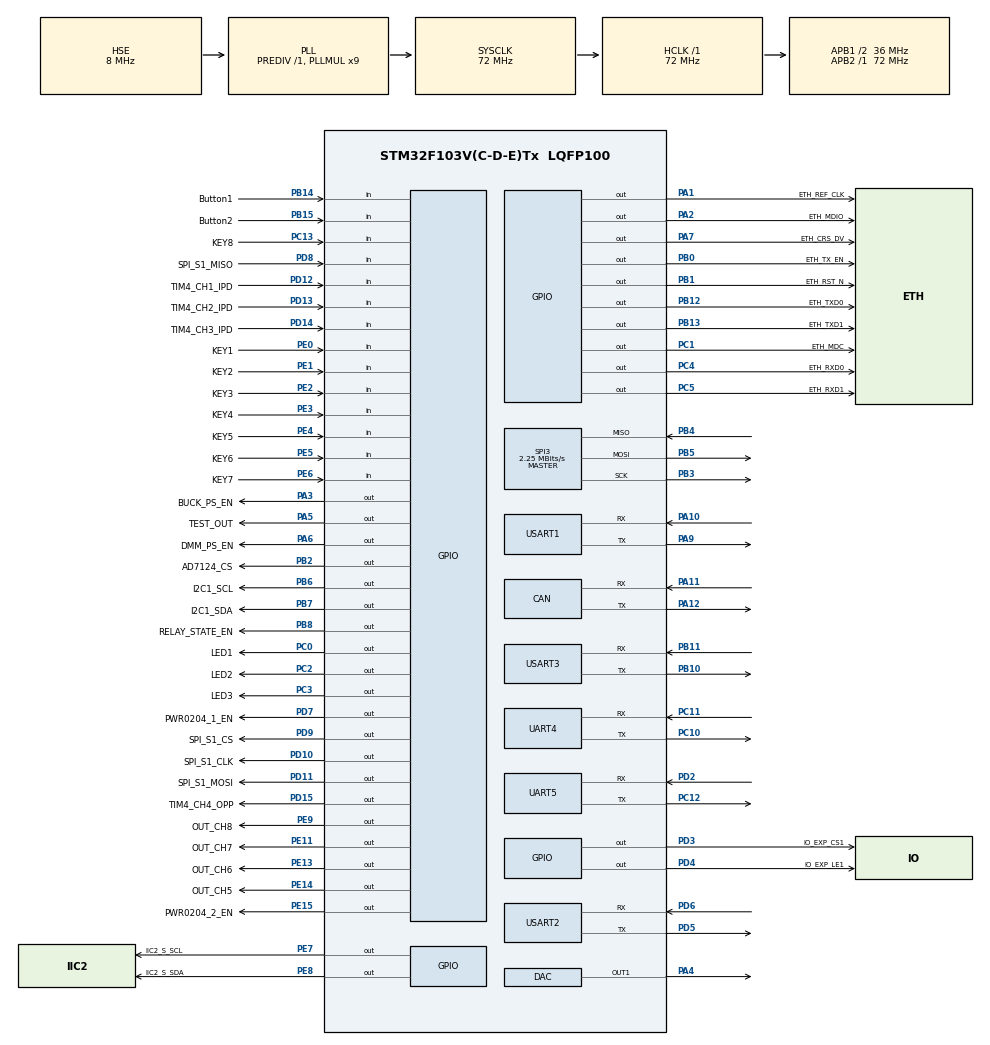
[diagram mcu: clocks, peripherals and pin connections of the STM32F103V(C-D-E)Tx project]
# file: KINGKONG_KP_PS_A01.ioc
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CAN.CalculateTimeBit=1333
CAN.CalculateTimeQuantum=444.44444444444446
DAC.DAC_Trigger=DAC_TRIGGER_NONE
FREERTOS.INCLUDE_vTaskDelayUntil=1
FREERTOS.Tasks01=defaultTask,0,128,StartDefaultTask,Default,NULL
FREERTOS.configTOTAL_HEAP_SIZE=15360
IWDG.Prescaler=IWDG_PRESCALER_32
IWDG.Reload=2500
Mcu.Family=STM32F1
Mcu.Name=STM32F103V(C-D-E)Tx
Mcu.Package=LQFP100
NVIC.PriorityGroup=NVIC_PRIORITYGROUP_4
NVIC.TIM6_IRQn=true\:0\:0\:false\:false\:true\:false\:false
NVIC.TimeBase=TIM6_IRQn
NVIC.TimeBaseIP=TIM6
NVIC.USART1_IRQn=true\:5\:0\:false\:false\:true\:true\:true
OSC_IN.Mode=HSE-External-Oscillator
OSC_IN.Signal=RCC_OSC_IN
OSC_OUT.Mode=HSE-External-Oscillator
OSC_OUT.Signal=RCC_OSC_OUT
PA1.GPIO_Label=ETH_REF_CLK
PA1.Signal=GPIO_Output
PA10.Mode=Asynchronous
PA10.Signal=USART1_RX
PA11.Mode=Master
PA11.Signal=CAN_RX
PA12.Mode=Master
PA12.Signal=CAN_TX
PA13.Mode=Serial_Wire
PA13.Signal=SYS_JTMS-SWDIO
PA14.Mode=Serial_Wire
PA14.Signal=SYS_JTCK-SWCLK
PA2.GPIO_Label=ETH_MDIO
PA2.Signal=GPIO_Output
PA3.GPIO_Label=BUCK_PS_EN
PA3.Signal=GPIO_Output
PA4.Signal=COMP_DAC1_group
PA5.GPIO_Label=TEST_OUT
PA5.GPIO_ModeDefaultOutputPP=GPIO_MODE_OUTPUT_PP
PA5.GPIO_Speed=GPIO_SPEED_FREQ_HIGH
PA5.Signal=GPIO_Output
PA6.GPIO_Label=DMM_PS_EN
PA6.GPIO_Speed=GPIO_SPEED_FREQ_HIGH
PA6.Signal=GPIO_Output
PA7.GPIO_Label=ETH_CRS_DV
PA7.Signal=GPIO_Output
PA9.Mode=Asynchronous
PA9.Signal=USART1_TX
PB0.GPIO_Label=ETH_TX_EN
PB0.Signal=GPIO_Output
PB1.GPIO_Label=ETH_RST_N
PB1.Signal=GPIO_Output
PB10.Mode=Asynchronous
PB10.Signal=USART3_TX
PB11.Mode=Asynchronous
PB11.Signal=USART3_RX
PB12.GPIO_Label=ETH_TXD0
PB12.Signal=GPIO_Output
PB13.GPIO_Label=ETH_TXD1
PB13.Signal=GPIO_Output
PB14.GPIO_Label=Button1
PB14.GPIO_Mode=GPIO_MODE_INPUT
PB14.GPIO_PuPd=GPIO_PULLUP
PB14.Signal=GPIO_Input
PB15.GPIO_Label=Button2
PB15.GPIO_Mode=GPIO_MODE_INPUT
PB15.GPIO_PuPd=GPIO_PULLUP
PB15.Signal=GPIO_Input
PB2.GPIO_Label=AD7124_CS
PB2.Signal=GPIO_Output
PB3.Mode=Full_Duplex_Master
PB3.Signal=SPI3_SCK
PB4.Mode=Full_Duplex_Master
PB4.Signal=SPI3_MISO
PB5.Mode=Full_Duplex_Master
PB5.Signal=SPI3_MOSI
PB6.GPIO_Label=I2C1_SCL
PB6.GPIO_ModeDefaultOutputPP=GPIO_MODE_OUTPUT_PP
PB6.GPIO_Speed=GPIO_SPEED_FREQ_HIGH
PB6.Signal=GPIO_Output
PB7.GPIO_Label=I2C1_SDA
PB7.GPIO_ModeDefaultOutputPP=GPIO_MODE_OUTPUT_PP
PB7.GPIO_Speed=GPIO_SPEED_FREQ_HIGH
PB7.Signal=GPIO_Output
PB8.GPIO_Label=RELAY_STATE_EN
PB8.GPIO_Speed=GPIO_SPEED_FREQ_HIGH
PB8.PinState=GPIO_PIN_RESET
PB8.Signal=GPIO_Output
PC0.GPIO_Label=LED1
PC0.GPIO_Speed=GPIO_SPEED_FREQ_HIGH
PC0.Signal=GPIO_Output
PC1.GPIO_Label=ETH_MDC
PC1.Signal=GPIO_Output
PC10.Mode=Asynchronous
PC10.Signal=UART4_TX
PC11.Mode=Asynchronous
PC11.Signal=UART4_RX
PC12.Mode=Asynchronous
PC12.Signal=UART5_TX
PC13-TAMPER-RTC.GPIO_Label=KEY8
PC13-TAMPER-RTC.Signal=GPIO_Input
PC2.GPIO_Label=LED2
PC2.GPIO_Speed=GPIO_SPEED_FREQ_HIGH
PC2.Signal=GPIO_Output
PC3.GPIO_Label=LED3
PC3.GPIO_Speed=GPIO_SPEED_FREQ_HIGH
PC3.Signal=GPIO_Output
PC4.GPIO_Label=ETH_RXD0
PC4.Signal=GPIO_Output
PC5.GPIO_Label=ETH_RXD1
PC5.Signal=GPIO_Output
PD10.GPIO_Label=SPI_S1_CLK
PD10.GPIO_Speed=GPIO_SPEED_FREQ_HIGH
PD10.Signal=GPIO_Output
PD11.GPIO_Label=SPI_S1_MOSI
PD11.GPIO_Speed=GPIO_SPEED_FREQ_HIGH
PD11.Signal=GPIO_Output
PD12.GPIO_Label=TIM4_CH1_IPD
PD12.GPIO_Mode=GPIO_MODE_INPUT
PD12.GPIO_PuPd=GPIO_PULLDOWN
PD12.Signal=GPIO_Input
PD13.GPIO_Label=TIM4_CH2_IPD
PD13.GPIO_Mode=GPIO_MODE_INPUT
PD13.GPIO_PuPd=GPIO_PULLDOWN
PD13.Signal=GPIO_Input
PD14.GPIO_Label=TIM4_CH3_IPD
PD14.GPIO_Mode=GPIO_MODE_INPUT
PD14.GPIO_PuPd=GPIO_PULLDOWN
PD14.Signal=GPIO_Input
PD15.GPIO_Label=TIM4_CH4_OPP
PD15.Signal=GPIO_Output
PD2.Mode=Asynchronous
PD2.Signal=UART5_RX
PD3.GPIO_Label=IO_EXP_CS1
PD3.GPIO_Speed=GPIO_SPEED_FREQ_HIGH
PD3.Signal=GPIO_Output
PD4.GPIO_Label=IO_EXP_LE1
PD4.GPIO_Speed=GPIO_SPEED_FREQ_HIGH
PD4.Signal=GPIO_Output
PD5.Mode=Asynchronous
PD5.Signal=USART2_TX
PD6.Mode=Asynchronous
PD6.Signal=USART2_RX
PD7.GPIO_Label=PWR0204_1_EN
PD7.GPIO_Speed=GPIO_SPEED_FREQ_HIGH
PD7.Signal=GPIO_Output
PD8.GPIO_Label=SPI_S1_MISO
PD8.Signal=GPIO_Input
PD9.GPIO_Label=SPI_S1_CS
PD9.GPIO_Speed=GPIO_SPEED_FREQ_HIGH
PD9.Signal=GPIO_Output
PE0.GPIO_Label=KEY1
PE0.Signal=GPIO_Input
PE1.GPIO_Label=KEY2
PE1.Signal=GPIO_Input
PE11.GPIO_Label=OUT_CH7
PE11.GPIO_ModeDefaultOutputPP=GPIO_MODE_OUTPUT_PP
PE11.GPIO_Speed=GPIO_SPEED_FREQ_HIGH
PE11.PinState=GPIO_PIN_RESET
PE11.Signal=GPIO_Output
PE13.GPIO_Label=OUT_CH6
PE13.GPIO_ModeDefaultOutputPP=GPIO_MODE_OUTPUT_PP
PE13.GPIO_Speed=GPIO_SPEED_FREQ_HIGH
PE13.PinState=GPIO_PIN_RESET
PE13.Signal=GPIO_Output
PE14.GPIO_Label=OUT_CH5
PE14.GPIO_ModeDefaultOutputPP=GPIO_MODE_OUTPUT_PP
PE14.GPIO_Speed=GPIO_SPEED_FREQ_HIGH
PE14.PinState=GPIO_PIN_RESET
PE14.Signal=GPIO_Output
PE15.GPIO_Label=PWR0204_2_EN
PE15.GPIO_Speed=GPIO_SPEED_FREQ_HIGH
PE15.Signal=GPIO_Output
PE2.GPIO_Label=KEY3
PE2.Signal=GPIO_Input
PE3.GPIO_Label=KEY4
PE3.Signal=GPIO_Input
PE4.GPIO_Label=KEY5
PE4.Signal=GPIO_Input
PE5.GPIO_Label=KEY6
PE5.Signal=GPIO_Input
PE6.GPIO_Label=KEY7
PE6.Signal=GPIO_Input
PE7.GPIO_Label=IIC2_S_SCL
PE7.GPIO_Speed=GPIO_SPEED_FREQ_HIGH
PE7.Signal=GPIO_Output
PE8.GPIO_Label=IIC2_S_SDA
PE8.GPIO_Speed=GPIO_SPEED_FREQ_HIGH
PE8.Signal=GPIO_Output
PE9.GPIO_Label=OUT_CH8
PE9.GPIO_ModeDefaultOutputPP=GPIO_MODE_OUTPUT_PP
PE9.GPIO_Speed=GPIO_SPEED_FREQ_HIGH
PE9.PinState=GPIO_PIN_RESET
PE9.Signal=GPIO_Output
ProjectManager.HeapSize=0x200
ProjectManager.StackSize=0x400
ProjectManager.TargetToolchain=MDK-ARM V5
RCC.AHBFreq_Value=72000000
RCC.APB1CLKDivider=RCC_HCLK_DIV2
RCC.APB1Freq_Value=36000000
RCC.APB1TimFreq_Value=72000000
RCC.APB2Freq_Value=72000000
RCC.APB2TimFreq_Value=72000000
RCC.HCLKFreq_Value=72000000
RCC.PLLMUL=RCC_PLL_MUL9
RCC.PLLSourceVirtual=RCC_PLLSOURCE_HSE
RCC.SYSCLKFreq_VALUE=72000000
RCC.SYSCLKSource=RCC_SYSCLKSOURCE_PLLCLK
RCC.USBFreq_Value=72000000
SH.COMP_DAC1_group.0=DAC_OUT1,DAC_OUT1
SPI3.BaudRatePrescaler=SPI_BAUDRATEPRESCALER_16
SPI3.CLKPhase=SPI_PHASE_2EDGE
SPI3.CLKPolarity=SPI_POLARITY_HIGH
SPI3.CalculateBaudRate=2.25 MBits/s
SPI3.Direction=SPI_DIRECTION_2LINES
SPI3.Mode=SPI_MODE_MASTER
SPI3.VirtualType=VM_MASTER
UART4.VirtualMode=Asynchronous
UART5.VirtualMode=Asynchronous
USART1.VirtualMode=VM_ASYNC
USART2.VirtualMode=VM_ASYNC
USART3.VirtualMode=VM_ASYNC
VP_FREERTOS_VS_ENABLE.Mode=Enabled
VP_IWDG_VS_IWDG.Mode=IWDG_Activate
VP_SYS_VS_tim6.Mode=TIM6
board=KINGKONG_KP_PS_A01

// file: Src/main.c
/* USER CODE BEGIN Header */
/**
  ******************************************************************************
  * @file           : main.c
  * @brief          : Main program body
  ******************************************************************************
  * This notice applies to any and all portions of this file
  * that are not between comment pairs USER CODE BEGIN and
  * USER CODE END. Other portions of this file, whether
  * inserted by the user or by software development tools
  * are owned by their respective copyright owners.
  *
  * Copyright (c) 2019 STMicroelectronics International N.V.
  * All rights reserved.
  *
  * Redistribution and use in source and binary forms, with or without
  * modification, are permitted, provided that the following conditions are met:
  *
  * 1. Redistribution of source code must retain the above copyright notice,
  *    this list of conditions and the following disclaimer.
  * 2. Redistributions in binary form must reproduce the above copyright notice,
  *    this list of conditions and the following disclaimer in the documentation
  *    and/or other materials provided with the distribution.
  * 3. Neither the name of STMicroelectronics nor the names of other
  *    contributors to this software may be used to endorse or promote products
  *    derived from this software without specific written permission.
  * 4. This software, including modifications and/or derivative works of this
  *    software, must execute solely and exclusively on microcontroller or
  *    microprocessor devices manufactured by or for STMicroelectronics.
  * 5. Redistribution and use of this software other than as permitted under
  *    this license is void and will automatically terminate your rights under
  *    this license.
  *
  * THIS SOFTWARE IS PROVIDED BY STMICROELECTRONICS AND CONTRIBUTORS "AS IS"
  * AND ANY EXPRESS, IMPLIED OR STATUTORY WARRANTIES, INCLUDING, BUT NOT
  * LIMITED TO, THE IMPLIED WARRANTIES OF MERCHANTABILITY, FITNESS FOR A
  * PARTICULAR PURPOSE AND NON-INFRINGEMENT OF THIRD PARTY INTELLECTUAL PROPERTY
  * RIGHTS ARE DISCLAIMED TO THE FULLEST EXTENT PERMITTED BY LAW. IN NO EVENT
  * SHALL STMICROELECTRONICS OR CONTRIBUTORS BE LIABLE FOR ANY DIRECT, INDIRECT,
  * INCIDENTAL, SPECIAL, EXEMPLARY, OR CONSEQUENTIAL DAMAGES (INCLUDING, BUT NOT
  * LIMITED TO, PROCUREMENT OF SUBSTITUTE GOODS OR SERVICES; LOSS OF USE, DATA,
  * OR PROFITS; OR BUSINESS INTERRUPTION) HOWEVER CAUSED AND ON ANY THEORY OF
  * LIABILITY, WHETHER IN CONTRACT, STRICT LIABILITY, OR TORT (INCLUDING
  * NEGLIGENCE OR OTHERWISE) ARISING IN ANY WAY OUT OF THE USE OF THIS SOFTWARE,
  * EVEN IF ADVISED OF THE POSSIBILITY OF SUCH DAMAGE.
  *
  ******************************************************************************
  */
/* USER CODE END Header */

#include "main.h"
#include "cmsis_os.h"
#include "can.h"
#include "dac.h"
#include "iwdg.h"
#include "spi.h"
#include "usart.h"
#include "gpio.h"

/* USER CODE BEGIN Includes */
//#include "bsp_uart.h"
#include "bootloader.h"
//#include "bsp_kingkong.h"
/* USER CODE END Includes */

/* USER CODE BEGIN PV */
/* Private variables ---------------------------------------------------------*/

/* USER CODE END PV */

void SystemClock_Config(void);
void MX_FREERTOS_Init(void);
/* USER CODE BEGIN PFP */
/* Private function prototypes -----------------------------------------------*/

/* USER CODE END PFP */

/* USER CODE BEGIN 0 */
extern void hardware_init(void);

/* USER CODE END 0 */

int main(void)
{

  /* MCU Configuration--------------------------------------------------------*/

  /* Reset of all peripherals, Initializes the Flash interface and the Systick. */
  HAL_Init();

  /* Configure the system clock */
  SystemClock_Config();

  /* USER CODE BEGIN SysInit */
	HAL_BOOT_LOADER();
	#ifndef BOOTLOADER
  /* USER CODE END SysInit */

  /* Initialize all configured peripherals */
  MX_GPIO_Init();
  MX_UART4_Init();
  MX_UART5_Init();
  MX_USART1_UART_Init();
  MX_USART2_UART_Init();
  MX_USART3_UART_Init();
  MX_CAN_Init();
  MX_DAC_Init();
  MX_SPI3_Init();
//  MX_IWDG_Init();
  /* USER CODE BEGIN 2 */

	hardware_init();
  /* USER CODE END 2 */

  /* Call init function for freertos objects (in freertos.c) */
  MX_FREERTOS_Init();

  /* Start scheduler */
  osKernelStart();

  /* We should never get here as control is now taken by the scheduler */

  /* Infinite loop */
  while (1)
  {

    /* USER CODE BEGIN 3 */
  }
	#endif
  /* USER CODE END 3 */
}

void SystemClock_Config(void)
{
  RCC_OscInitTypeDef RCC_OscInitStruct = {0};
  RCC_ClkInitTypeDef RCC_ClkInitStruct = {0};

  /**Initializes the CPU, AHB and APB busses clocks
  */
  RCC_OscInitStruct.OscillatorType = RCC_OSCILLATORTYPE_LSI|RCC_OSCILLATORTYPE_HSE;
  RCC_OscInitStruct.HSEState = RCC_HSE_ON;
  RCC_OscInitStruct.HSEPredivValue = RCC_HSE_PREDIV_DIV1;
  RCC_OscInitStruct.HSIState = RCC_HSI_ON;
  RCC_OscInitStruct.LSIState = RCC_LSI_ON;
  RCC_OscInitStruct.PLL.PLLState = RCC_PLL_ON;
  RCC_OscInitStruct.PLL.PLLSource = RCC_PLLSOURCE_HSE;
  RCC_OscInitStruct.PLL.PLLMUL = RCC_PLL_MUL9;
  if (HAL_RCC_OscConfig(&RCC_OscInitStruct) != HAL_OK)
  {
    Error_Handler();
  }
  /**Initializes the CPU, AHB and APB busses clocks
  */
  RCC_ClkInitStruct.ClockType = RCC_CLOCKTYPE_HCLK|RCC_CLOCKTYPE_SYSCLK
                              |RCC_CLOCKTYPE_PCLK1|RCC_CLOCKTYPE_PCLK2;
  RCC_ClkInitStruct.SYSCLKSource = RCC_SYSCLKSOURCE_PLLCLK;
  RCC_ClkInitStruct.AHBCLKDivider = RCC_SYSCLK_DIV1;
  RCC_ClkInitStruct.APB1CLKDivider = RCC_HCLK_DIV2;
  RCC_ClkInitStruct.APB2CLKDivider = RCC_HCLK_DIV1;

  if (HAL_RCC_ClockConfig(&RCC_ClkInitStruct, FLASH_LATENCY_2) != HAL_OK)
  {
    Error_Handler();
  }
}

void HAL_TIM_PeriodElapsedCallback(TIM_HandleTypeDef *htim)
{
  if (htim->Instance == TIM6) {
    HAL_IncTick();
  }
}

void Error_Handler(void)
{
  while(1)
  {
  }
}

/************************ (C) COPYRIGHT STMicroelectronics *****END OF FILE****/

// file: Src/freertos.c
/* USER CODE BEGIN Header */
/**
  ******************************************************************************
  * File Name          : freertos.c
  * Description        : Code for freertos applications
  ******************************************************************************
  * This notice applies to any and all portions of this file
  * that are not between comment pairs USER CODE BEGIN and
  * USER CODE END. Other portions of this file, whether
  * inserted by the user or by software development tools
  * are owned by their respective copyright owners.
  *
  * Copyright (c) 2019 STMicroelectronics International N.V.
  * All rights reserved.
  *
  * Redistribution and use in source and binary forms, with or without
  * modification, are permitted, provided that the following conditions are met:
  *
  * 1. Redistribution of source code must retain the above copyright notice,
  *    this list of conditions and the following disclaimer.
  * 2. Redistributions in binary form must reproduce the above copyright notice,
  *    this list of conditions and the following disclaimer in the documentation
  *    and/or other materials provided with the distribution.
  * 3. Neither the name of STMicroelectronics nor the names of other
  *    contributors to this software may be used to endorse or promote products
  *    derived from this software without specific written permission.
  * 4. This software, including modifications and/or derivative works of this
  *    software, must execute solely and exclusively on microcontroller or
  *    microprocessor devices manufactured by or for STMicroelectronics.
  * 5. Redistribution and use of this software other than as permitted under
  *    this license is void and will automatically terminate your rights under
  *    this license.
  *
  * THIS SOFTWARE IS PROVIDED BY STMICROELECTRONICS AND CONTRIBUTORS "AS IS"
  * AND ANY EXPRESS, IMPLIED OR STATUTORY WARRANTIES, INCLUDING, BUT NOT
  * LIMITED TO, THE IMPLIED WARRANTIES OF MERCHANTABILITY, FITNESS FOR A
  * PARTICULAR PURPOSE AND NON-INFRINGEMENT OF THIRD PARTY INTELLECTUAL PROPERTY
  * RIGHTS ARE DISCLAIMED TO THE FULLEST EXTENT PERMITTED BY LAW. IN NO EVENT
  * SHALL STMICROELECTRONICS OR CONTRIBUTORS BE LIABLE FOR ANY DIRECT, INDIRECT,
  * INCIDENTAL, SPECIAL, EXEMPLARY, OR CONSEQUENTIAL DAMAGES (INCLUDING, BUT NOT
  * LIMITED TO, PROCUREMENT OF SUBSTITUTE GOODS OR SERVICES; LOSS OF USE, DATA,
  * OR PROFITS; OR BUSINESS INTERRUPTION) HOWEVER CAUSED AND ON ANY THEORY OF
  * LIABILITY, WHETHER IN CONTRACT, STRICT LIABILITY, OR TORT (INCLUDING
  * NEGLIGENCE OR OTHERWISE) ARISING IN ANY WAY OUT OF THE USE OF THIS SOFTWARE,
  * EVEN IF ADVISED OF THE POSSIBILITY OF SUCH DAMAGE.
  *
  ******************************************************************************
  */
/* USER CODE END Header */

#include "FreeRTOS.h"
#include "task.h"
#include "main.h"
#include "cmsis_os.h"

/* USER CODE BEGIN Includes */
#include "app_test_procedure.h"

/* USER CODE END Includes */

osThreadId defaultTaskHandle;

void StartDefaultTask(void const * argument);

void MX_FREERTOS_Init(void); /* (MISRA C 2004 rule 8.1) */

void MX_FREERTOS_Init(void) {

  /* Create the thread(s) */
  /* definition and creation of defaultTask */
  osThreadDef(defaultTask, StartDefaultTask, osPriorityNormal, 0, 128);
  defaultTaskHandle = osThreadCreate(osThread(defaultTask), NULL);

  /* USER CODE BEGIN RTOS_THREADS */
  /* add threads, ... */
	initTaskThreadCreate(osPriorityHigh);
  /* USER CODE END RTOS_THREADS */

}

void StartDefaultTask(void const * argument)
{

  for(;;)
  {
    osDelay(1);
  }
}

/************************ (C) COPYRIGHT STMicroelectronics *****END OF FILE****/
